AUTOSAR XML (schema 4-0-3)
standard types defined: UInt8
package /AUTOSAR_Platform/DataConstrs
  range DC_UInt8: raw 0..255
package /PATAC/Facility/DataTypes/Implementation
  unit NoUnit: factor-si-to-unit=1, offset-si-to-unit=0
package /PATAC/MSM/ComponentTypes
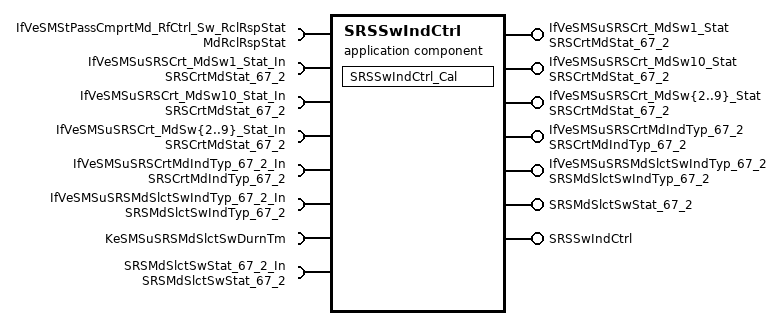
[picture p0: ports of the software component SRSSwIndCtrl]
  application sw component type SRSSwIndCtrl
    14 x provide port:
      IfVeSMSuSRSCrt_MdSw1_Stat: nonqueued-sender-com-spec{data-element=SRSCrtMdStat_67_2/Val, init-value=0}, provided-interface=SRSCrtMdStat_67_2
      IfVeSMSuSRSCrt_MdSw10_Stat: nonqueued-sender-com-spec{data-element=SRSCrtMdStat_67_2/Val, init-value=0}, provided-interface=SRSCrtMdStat_67_2
      IfVeSMSuSRSCrt_MdSw{2..9}_Stat: nonqueued-sender-com-spec{data-element=SRSCrtMdStat_67_2/Val, init-value=0}, provided-interface=SRSCrtMdStat_67_2
      IfVeSMSuSRSCrtMdIndTyp_67_2: nonqueued-sender-com-spec{data-element=SRSCrtMdIndTyp_67_2/Val, init-value=0}, provided-interface=SRSCrtMdIndTyp_67_2
      IfVeSMSuSRSMdSlctSwIndTyp_67_2: nonqueued-sender-com-spec{data-element=SRSMdSlctSwIndTyp_67_2/Val, init-value=1}, provided-interface=SRSMdSlctSwIndTyp_67_2
      SRSMdSlctSwStat_67_2: nonqueued-sender-com-spec{data-element=SRSMdSlctSwStat_67_2/Val, init-value=0}, provided-interface=SRSMdSlctSwStat_67_2
      SRSSwIndCtrl: server-com-spec{operation=Cal, queue-length=1}, provided-interface=SRSSwIndCtrl
    15 x require port:
      IfVeSMStPassCmprtMd_RfCtrl_Sw_RclRspStat: nonqueued-receiver-com-spec{data-element=MdRclRspStat/Val, filter=data-filter-type=ALWAYS, init-value=0}, required-interface=MdRclRspStat
      IfVeSMSuSRSCrt_MdSw1_Stat_In: nonqueued-receiver-com-spec{data-element=SRSCrtMdStat_67_2/Val, filter=data-filter-type=ALWAYS, init-value=0}, required-interface=SRSCrtMdStat_67_2
      IfVeSMSuSRSCrt_MdSw10_Stat_In: nonqueued-receiver-com-spec{data-element=SRSCrtMdStat_67_2/Val, filter=data-filter-type=ALWAYS, init-value=0}, required-interface=SRSCrtMdStat_67_2
      IfVeSMSuSRSCrt_MdSw{2..9}_Stat_In: nonqueued-receiver-com-spec{data-element=SRSCrtMdStat_67_2/Val, filter=data-filter-type=ALWAYS, init-value=0}, required-interface=SRSCrtMdStat_67_2
      IfVeSMSuSRSCrtMdIndTyp_67_2_In: nonqueued-receiver-com-spec{data-element=SRSCrtMdIndTyp_67_2/Val, filter=data-filter-type=ALWAYS, init-value=0}, required-interface=SRSCrtMdIndTyp_67_2
      IfVeSMSuSRSMdSlctSwIndTyp_67_2_In: nonqueued-receiver-com-spec{data-element=SRSMdSlctSwIndTyp_67_2/Val, filter=data-filter-type=ALWAYS, init-value=1}, required-interface=SRSMdSlctSwIndTyp_67_2
      KeSMSuSRSMdSlctSwDurnTm: parameter-require-com-spec{init-value=20, parameter=Val}, required-interface=KeSMSuSRSMdSlctSwDurnTm
      SRSMdSlctSwStat_67_2_In: nonqueued-receiver-com-spec{data-element=SRSMdSlctSwStat_67_2/Val, filter=data-filter-type=ALWAYS, init-value=0}, required-interface=SRSMdSlctSwStat_67_2
    behavior SRSSwIndCtrl_InternalBehavior
      operation invoked event OIT_SRSSwIndCtrl_Cal_SRSSwIndCtrl_Cal: start-on-event=SRSSwIndCtrl_Cal, operation=SRSSwIndCtrl.Cal
      runnable SRSSwIndCtrl_Cal
        data-receive-point-by-arguments:
          14 x access:
            REC_IfVeSMStPassCmprtMd_RfCtrl_Sw_RclRspStat_Val: accessed-variable=IfVeSMStPassCmprtMd_RfCtrl_Sw_RclRspStat.Val
            REC_IfVeSMSuSRSCrt_MdSw1_Stat_In_Val: accessed-variable=IfVeSMSuSRSCrt_MdSw1_Stat_In.Val
            REC_IfVeSMSuSRSCrt_MdSw10_Stat_In_Val: accessed-variable=IfVeSMSuSRSCrt_MdSw10_Stat_In.Val
            REC_IfVeSMSuSRSCrt_MdSw{2..9}_Stat_In_Val: accessed-variable=IfVeSMSuSRSCrt_MdSw{2..9}_Stat_In.Val
            REC_IfVeSMSuSRSCrtMdIndTyp_67_2_In_Val: accessed-variable=IfVeSMSuSRSCrtMdIndTyp_67_2_In.Val
            REC_IfVeSMSuSRSMdSlctSwIndTyp_67_2_In_Val: accessed-variable=IfVeSMSuSRSMdSlctSwIndTyp_67_2_In.Val
            REC_SRSMdSlctSwStat_67_2_In_Val: accessed-variable=SRSMdSlctSwStat_67_2_In.Val
        data-send-points:
          13 x access:
            SEND_IfVeSMSuSRSCrt_MdSw1_Stat_Val: accessed-variable=IfVeSMSuSRSCrt_MdSw1_Stat.Val
            SEND_IfVeSMSuSRSCrt_MdSw10_Stat_Val: accessed-variable=IfVeSMSuSRSCrt_MdSw10_Stat.Val
            SEND_IfVeSMSuSRSCrt_MdSw{2..9}_Stat_Val: accessed-variable=IfVeSMSuSRSCrt_MdSw{2..9}_Stat.Val
            SEND_IfVeSMSuSRSCrtMdIndTyp_67_2_Val: accessed-variable=IfVeSMSuSRSCrtMdIndTyp_67_2.Val
            SEND_IfVeSMSuSRSMdSlctSwIndTyp_67_2_Val: accessed-variable=IfVeSMSuSRSMdSlctSwIndTyp_67_2.Val
            SEND_SRSMdSlctSwStat_67_2_Val: accessed-variable=SRSMdSlctSwStat_67_2.Val
        parameter access PA_KeSMSuSRSMdSlctSwDurnTm_Val: accessed-parameter=KeSMSuSRSMdSlctSwDurnTm.Val
  swc implementation SRSSwIndCtrl_Implementation: behavior=SRSSwIndCtrl_InternalBehavior
    code-descriptors:
      code Default: artifact-descriptors=autosar-engineering-object={short-label=Default, category=SWSRC}
package /PATAC/MSM/ModeAdjust/CalPortInterface
  parameter interface KeSMSuSRSMdSlctSwDurnTm
    parameter data prototype Val: sw-calibration-access=READ-WRITE, type=UInt8
package /PATAC/MSM/ModeAdjust/DataType
  impl type SRSIndicatorStat:
    category=VALUE
    base-type=UInt8
    sw-calibration-access=READ-ONLY
    compu {0=SRSIndicatorStat_NoIndicator, 1=SRSIndicatorStat_Mode1On, 2=SRSIndicatorStat_Mode2On, 3=SRSIndicatorStat_Mode3On, 4=SRSIndicatorStat_Mode4On, 5=SRSIndicatorStat_Mode5On, 6=SRSIndicatorStat_Mode6On, 7=SRSIndicatorStat_Mode7On, 8=SRSIndicatorStat_Mode8On, 9=SRSIndicatorStat_Mode9On, 10=SRSIndicatorStat_Mode10On, 11..15=Reserved1..Reserved5}
    type-emitter=RTE
  impl type SRSSlctSwIndTyp: category=VALUE, base-type=UInt8, sw-calibration-access=READ-ONLY, compu {0=IndicationOff, 1=FlashRate1, 2=FlashRate2, 3=Continuous}, type-emitter=RTE
package /PATAC/MSM/ModeAdjust/PortInterface
  client server interface SRSSwIndCtrl
    operation Cal
  5 x sender receiver interface:
    MdRclRspStat: invalidation-policy{data-element=MdRclRspStat/Val, handle-invalid=DONT-INVALIDATE}
      data Val: type=UInt8
    SRSCrtMdIndTyp_67_2: invalidation-policy{data-element=SRSCrtMdIndTyp_67_2/Val, handle-invalid=DONT-INVALIDATE}
      data Val: type=UInt8
    SRSCrtMdStat_67_2: invalidation-policy{data-element=SRSCrtMdStat_67_2/Val, handle-invalid=DONT-INVALIDATE}
      data Val: type=UInt8
    SRSMdSlctSwIndTyp_67_2: invalidation-policy{data-element=SRSMdSlctSwIndTyp_67_2/Val, handle-invalid=DONT-INVALIDATE}
      data Val: type=SRSSlctSwIndTyp
    SRSMdSlctSwStat_67_2: invalidation-policy{data-element=SRSMdSlctSwStat_67_2/Val, handle-invalid=DONT-INVALIDATE}
      data Val: type=SRSIndicatorStat
